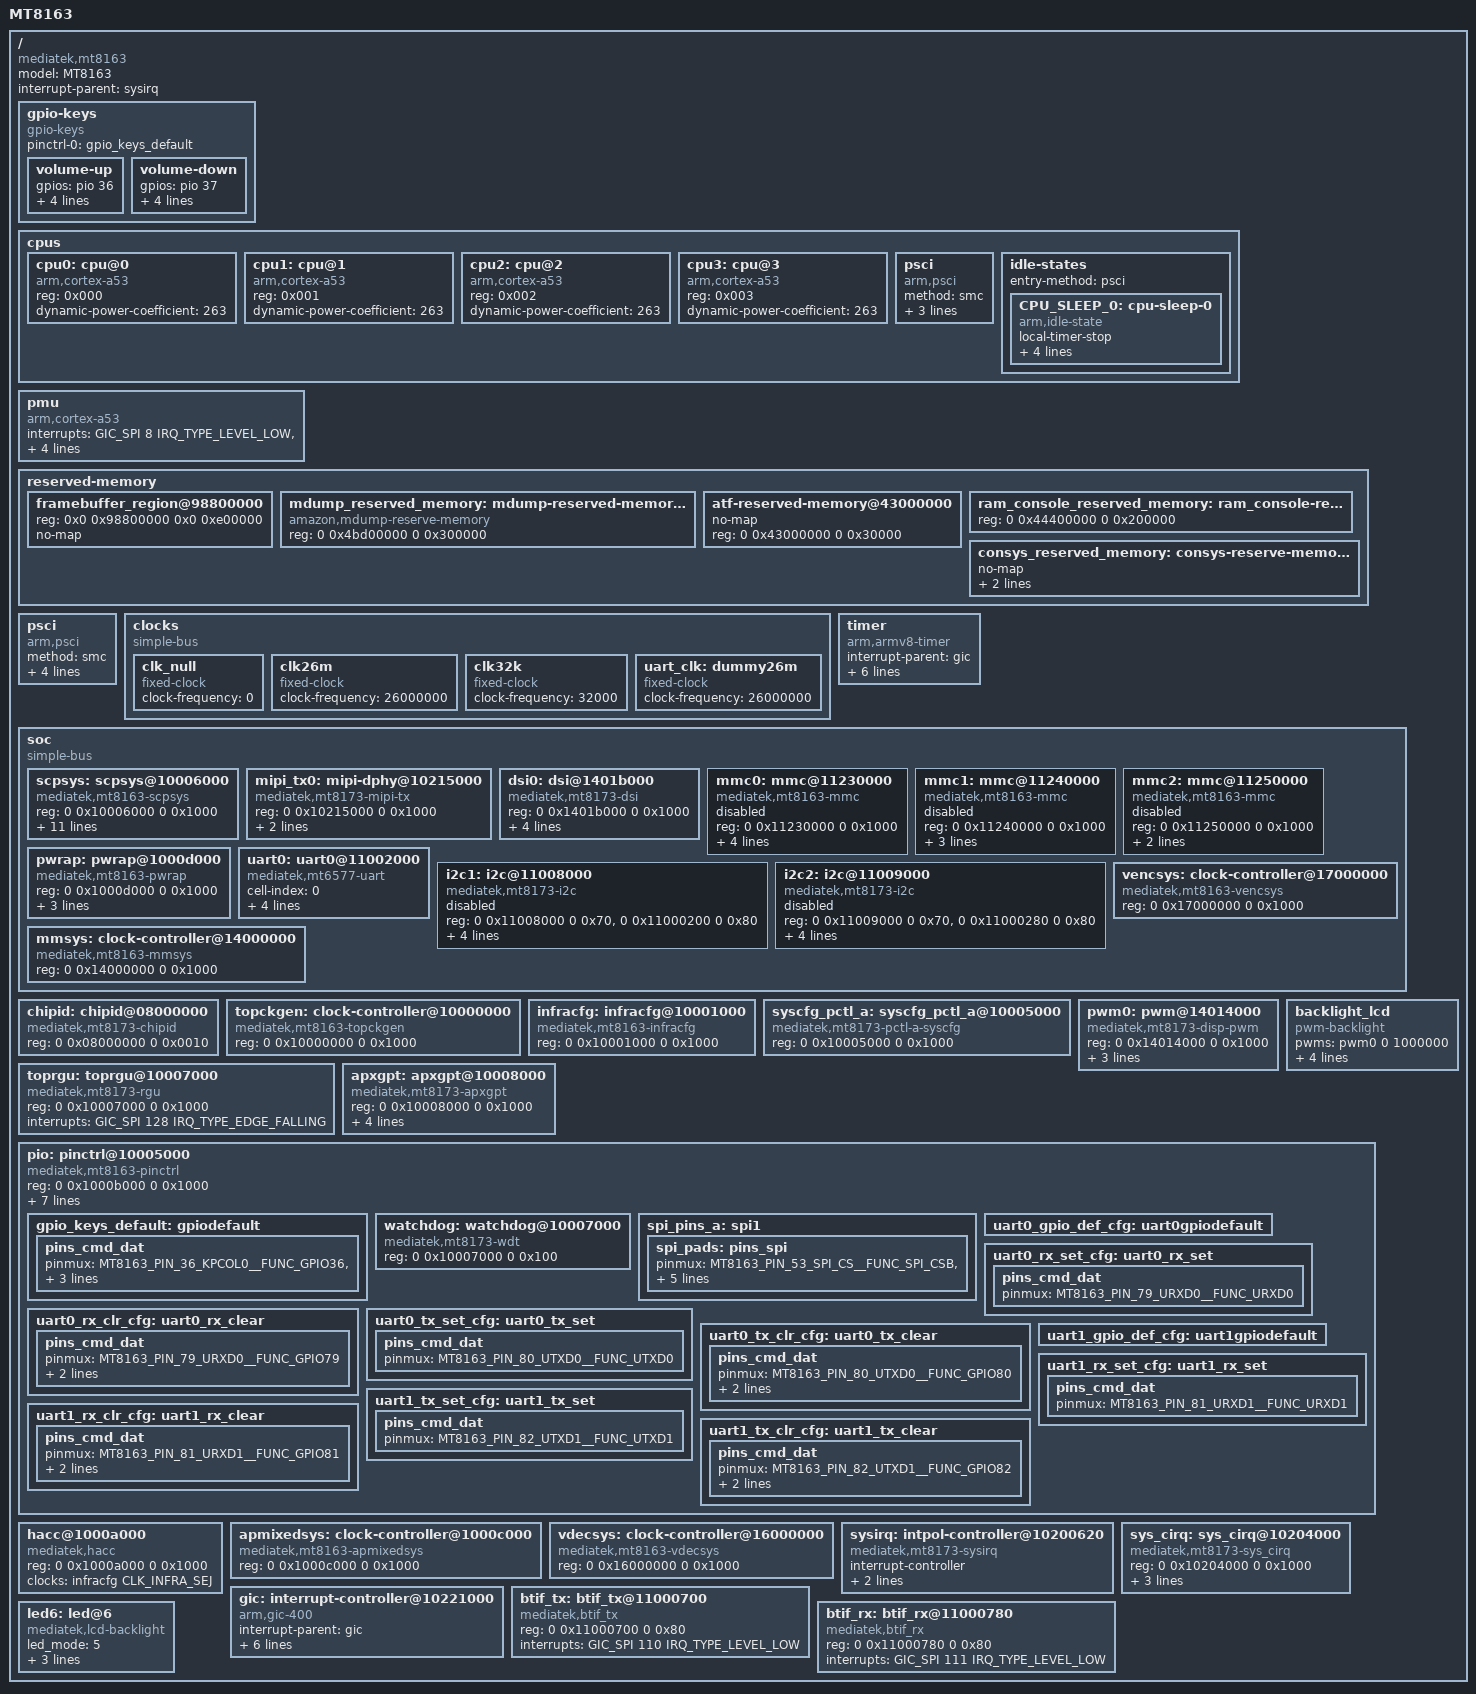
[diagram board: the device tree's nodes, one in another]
/*
 * Mediatek's MT8163 SoC device tree source
 * Copyright (c) 2014-2015 MediaTek Inc.
 *
 * This program is free software; you can redistribute it and/or modify
 * it under the terms of the GNU General Public License version 2 as
 * published by the Free Software Foundation.
 *
 * This program is distributed in the hope that it will be useful,
 * MERCHANTABILITY or FITNESS FOR A PARTICULAR PURPOSE.  See the
 * GNU General Public License for more details.
 */

#include <dt-bindings/clock/mt8163-clk.h>
#include <dt-bindings/power/mt8163-power.h>
#include <dt-bindings/interrupt-controller/irq.h>
#include <dt-bindings/interrupt-controller/arm-gic.h>
#include <dt-bindings/reset-controller/mt8163-resets.h>
#include "mt8163-pinfunc.h"
#include <dt-bindings/gpio/gpio.h> 
/ {
	model = "MT8163";
	compatible = "mediatek,mt8163";
	interrupt-parent = <&sysirq>;
	#address-cells = <2>;
	#size-cells = <2>;
        gpio-keys {
		    compatible = "gpio-keys";
		    pinctrl-names = "default";
		    pinctrl-0 = <&gpio_keys_default>;

		    volume-up {
			    gpios = <&pio 36 GPIO_ACTIVE_HIGH>;
			    label = "volume_up";
			    linux,code = <115>;
			    wakeup-source;
			    debounce-interval = <15>;
		    };

		    volume-down {
			    gpios = <&pio 37 GPIO_ACTIVE_HIGH>;
			    label = "volume_down";
			    linux,code = <114>;
			    wakeup-source;
			debounce-interval = <15>;
		};	
};
	cpus {
		#address-cells = <1>;
		#size-cells = <0>;
		cpu0: cpu@0 {
			device_type = "cpu";
			compatible = "arm,cortex-a53";
			reg = <0x000>;
	//		enable-method = "psci";
			dynamic-power-coefficient = <263>;
		};
        cpu1: cpu@1 {
			device_type = "cpu";
			compatible = "arm,cortex-a53";
			reg = <0x001>;
		//	enable-method = "psci";
			dynamic-power-coefficient = <263>;
		};

		cpu2: cpu@2 {
			device_type = "cpu";
			compatible = "arm,cortex-a53";
			reg = <0x002>;
			//enable-method = "psci";
			dynamic-power-coefficient = <263>;
		};
		cpu3: cpu@3 {
			device_type = "cpu";
			compatible = "arm,cortex-a53";
			reg = <0x003>;
			//enable-method = "psci";
			dynamic-power-coefficient = <263>;
		};
	psci {
		compatible  = "arm,psci";
		method      = "smc";
		cpu_suspend = <0x84000001>;
		cpu_off     = <0x84000002>;
		cpu_on      = <0x84000003>;
	};

		idle-states {
			entry-method = "psci";

			CPU_SLEEP_0: cpu-sleep-0 {
				compatible = "arm,idle-state";
				local-timer-stop;
				entry-latency-us = <639>;
				exit-latency-us = <680>;
				min-residency-us = <1088>;
				arm,psci-suspend-param = <0x0010000>;
			};
		};
	};


	pmu {
		compatible = "arm,cortex-a53";
		interrupts = <GIC_SPI 8 IRQ_TYPE_LEVEL_LOW>,
			<GIC_SPI 9 IRQ_TYPE_LEVEL_LOW>,
			<GIC_SPI 10 IRQ_TYPE_LEVEL_LOW>,
			<GIC_SPI 11 IRQ_TYPE_LEVEL_LOW>;
		interrupt-affinity = <&cpu0>,
				<&cpu1>,
				<&cpu2>,
				<&cpu3>;
	};
	
	reserved-memory {
		#address-cells = <2>;
		#size-cells = <2>;
		ranges;
		framebuffer_region@98800000 {
			reg = <0x0 0x98800000 0x0 0xe00000>;
			no-map;
		};

		mdump_reserved_memory: mdump-reserved-memory@4bd00000 {
			compatible = "amazon,mdump-reserve-memory";
			reg = <0 0x4bd00000 0 0x300000>;
		};

		atf-reserved-memory@43000000 {
			no-map;
			reg = <0 0x43000000 0 0x30000>;
		};

		ram_console_reserved_memory: ram_console-reserved-memory@44400000{
			reg = <0 0x44400000 0 0x200000>;
		};

		consys_reserved_memory: consys-reserve-memory {
			no-map;
			size = <0 0x200000>;
			alignment = <0 0x200000>;
		};
	};

	psci {
		compatible  = "arm,psci";
		method      = "smc";
		cpu_suspend = <0x84000001>;
		cpu_off     = <0x84000002>;
		cpu_on      = <0x84000003>;
		affinity_info = <0x84000004>;
	};

	clocks {
		#address-cells = <2>;
		#size-cells = <2>;
		compatible = "simple-bus";
		ranges;

		clk_null: clk_null {
			compatible = "fixed-clock";
			#clock-cells = <0>;
			clock-frequency = <0>;
		};

		clk26m: clk26m {
			compatible = "fixed-clock";
			#clock-cells = <0>;
			clock-frequency = <26000000>;
		};

		clk32k: clk32k {
			compatible = "fixed-clock";
			#clock-cells = <0>;
			clock-frequency = <32000>;
		};

		uart_clk: dummy26m {
			compatible = "fixed-clock";
			clock-frequency = <26000000>;
			#clock-cells = <0>;
		};
	};
	
	

	timer {
		compatible = "arm,armv8-timer";
		interrupt-parent = <&gic>;
		interrupts = <GIC_PPI 13
			     (GIC_CPU_MASK_SIMPLE(4) | IRQ_TYPE_LEVEL_LOW)>,
			     <GIC_PPI 14
			     (GIC_CPU_MASK_SIMPLE(4) | IRQ_TYPE_LEVEL_LOW)>,
			     <GIC_PPI 11
			     (GIC_CPU_MASK_SIMPLE(4) | IRQ_TYPE_LEVEL_LOW)>,
			     <GIC_PPI 10
			     (GIC_CPU_MASK_SIMPLE(4) | IRQ_TYPE_LEVEL_LOW)>;
		clock-frequency = <13000000>;
	};

	soc {
		#address-cells = <2>;
		#size-cells = <2>;
		compatible = "simple-bus";
		ranges;

		scpsys: scpsys@10006000 {
			compatible = "mediatek,mt8163-scpsys", "syscon";
			#power-domain-cells = <1>;
			reg = <0 0x10006000 0 0x1000>;
			interrupts =	<GIC_SPI 163 IRQ_TYPE_LEVEL_LOW>,
					<GIC_SPI 164 IRQ_TYPE_LEVEL_LOW>,
					<GIC_SPI 165 IRQ_TYPE_LEVEL_LOW>,
					<GIC_SPI 166 IRQ_TYPE_LEVEL_LOW>,
					<GIC_SPI 167 IRQ_TYPE_LEVEL_LOW>,
					<GIC_SPI 168 IRQ_TYPE_LEVEL_LOW>,
					<GIC_SPI 169 IRQ_TYPE_LEVEL_LOW>,
					<GIC_SPI 170 IRQ_TYPE_LEVEL_LOW>;
			infracfg = <&infracfg>;
			clocks = <&topckgen CLK_TOP_MFG_SEL>,
				 <&topckgen CLK_TOP_MM_SEL>;
			clock-names = "mfg", "mm";
		};
mipi_tx0: mipi-dphy@10215000 {
			compatible = "mediatek,mt8173-mipi-tx";
			reg = <0 0x10215000 0 0x1000>;
			clocks = <&clk26m>;
			clock-output-names = "mipi_tx0_pll";
			#clock-cells = <0>;
			#phy-cells = <0>;
			status = "okay";
		};
dsi0: dsi@1401b000 {
	compatible = "mediatek,mt8173-dsi";
	reg = <0 0x1401b000 0 0x1000>;
	interrupts = <GIC_SPI 192 IRQ_TYPE_LEVEL_LOW>;
			clocks = <&mmsys CLK_MM_DSI_ENGINE>,
				 <&mmsys CLK_MM_DSI_DIGITAL>,
				 <&mipi_tx0>;
	clock-names = "engine", "digital", "hs";
	phys = <&mipi_tx0>;
	phy-names = "dphy";

};
			mmc0: mmc@11230000 {
			compatible = "mediatek,mt8163-mmc";
			reg = <0 0x11230000 0 0x1000>;
			interrupts = <GIC_SPI 79 IRQ_TYPE_LEVEL_LOW>;
			infracfg = <&infracfg>;
			clocks = <&infracfg CLK_INFRA_MSDC3>,
					<&infracfg CLK_INFRA_MSDC0>,
					<&clk_null>;
			clock-names = "extra", "source", "hclk";
			status = "disabled";
		};

		mmc1: mmc@11240000 {
			compatible = "mediatek,mt8163-mmc";
			reg = <0 0x11240000 0 0x1000>;
			interrupts = <GIC_SPI 80 IRQ_TYPE_LEVEL_LOW>;
			clocks = <&infracfg CLK_INFRA_MSDC1>,
					<&topckgen CLK_TOP_AXI_SEL>,
                    <&clk_null>;
			clock-names = "extra", "source", "hclk";
			status = "disabled";
		};

        mmc2: mmc@11250000 {
            compatible = "mediatek,mt8163-mmc";
            reg = <0 0x11250000 0 0x1000>;
            interrupts = <GIC_SPI 81 IRQ_TYPE_LEVEL_LOW>;
            clocks = <&infracfg CLK_INFRA_MSDC2>,
                     <&clk_null>;
           clock-names = "source", "hclk";
           status = "disabled";
           };
		pwrap: pwrap@1000d000 {
			compatible = "mediatek,mt8163-pwrap";
			reg = <0 0x1000d000 0 0x1000>;
			reg-names = "pwrap";
			interrupts = <GIC_SPI 161 IRQ_TYPE_LEVEL_HIGH>;
			clocks = <&topckgen CLK_TOP_PMICSPI_SEL>,
				 <&infracfg CLK_INFRA_PMIC_AP>;
			clock-names = "spi",
				      "wrap";
		};
		uart0: uart0@11002000 {
			cell-index = <0>;
			compatible = "mediatek,mt6577-uart";
			reg = <0 0x11002000 0 0x400>; /* UART base */
			interrupts = <GIC_SPI 91 IRQ_TYPE_LEVEL_LOW>;
			clocks = <&infracfg CLK_INFRA_UART0_SEL>, <&infracfg CLK_INFRA_UART0>;
			clock-names = "baud", "bus";
			status = "okay";
		};
        i2c1: i2c@11008000 {
			compatible = "mediatek,mt8173-i2c";
			reg = <0 0x11008000 0 0x70>,
			      <0 0x11000200 0 0x80>;
			interrupts = <GIC_SPI 85 IRQ_TYPE_LEVEL_LOW>;
			clock-div = <8>;
			clocks = <&infracfg CLK_INFRA_I2C1>, <&infracfg CLK_INFRA_AP_DMA>;
			clock-names = "main", "dma";
			#address-cells = <1>;
			#size-cells = <0>;
			status = "disabled";
		};
		i2c2: i2c@11009000 {
			compatible = "mediatek,mt8173-i2c";
			reg = <0 0x11009000 0 0x70>,
			      <0 0x11000280 0 0x80>;
			interrupts = <GIC_SPI 86 IRQ_TYPE_LEVEL_LOW>;
			clock-div = <10>;
			clocks = <&infracfg CLK_INFRA_I2C2>, <&infracfg CLK_INFRA_AP_DMA>;
			clock-names = "main", "dma";
			#address-cells = <1>;
			#size-cells = <0>;
			status = "disabled";
		};
		vencsys: clock-controller@17000000 {
			compatible = "mediatek,mt8163-vencsys", "syscon";
			reg = <0 0x17000000 0 0x1000>;
			#clock-cells = <1>;
		};
		mmsys: clock-controller@14000000 {
			compatible = "mediatek,mt8163-mmsys", "syscon";
			reg = <0 0x14000000 0 0x1000>;
			#clock-cells = <1>;
		};

		};
		chipid: chipid@08000000 {
			compatible = "mediatek,mt8173-chipid";
			reg = <0 0x08000000 0 0x0010>;
		};

		topckgen: clock-controller@10000000 {
			compatible = "mediatek,mt8163-topckgen";
			reg = <0 0x10000000 0 0x1000>;
			#clock-cells = <1>;
		};

		infracfg: infracfg@10001000 {
			compatible = "mediatek,mt8163-infracfg", "syscon";
			reg = <0 0x10001000 0 0x1000>;
			#clock-cells = <1>;
			#reset-cells = <1>;
		};

		syscfg_pctl_a: syscfg_pctl_a@10005000 {
			compatible = "mediatek,mt8173-pctl-a-syscfg", "syscon";
			reg = <0 0x10005000 0 0x1000>;
		};
        pwm0: pwm@14014000 {
			compatible ="mediatek,mt8173-disp-pwm",
                        "mediatek,mt6595-disp-pwm";
			reg = <0 0x14014000 0 0x1000>;
			#pwm-cells = <2>;
			clocks = <&mmsys CLK_MM_DISP_PWM_26M>,
				 <&mmsys CLK_MM_DISP_PWM_MM>;
			clock-names = "main", "mm";
		    pinctrl-names = "default";
	        pinctrl-0 = <&disp_pwm0_pins>;
	        status = "okay";
		};
     	backlight_lcd: backlight_lcd {
		compatible = "pwm-backlight";
		pwms = <&pwm0 0 1000000>;
		brightness-levels = <
			  0  16  32  48  64  80  96 112
			128 144 160 176 192 208 224 240
			255
		>;
		default-brightness-level = <9>;
		power-supply = <&mt6323_vio18_reg>;

	};
		toprgu: toprgu@10007000 {
			compatible = "mediatek,mt8173-rgu";
			reg = <0 0x10007000 0 0x1000>;
			interrupts = <GIC_SPI 128 IRQ_TYPE_EDGE_FALLING>;
			#reset-cells = <1>;
		};

		apxgpt: apxgpt@10008000 {
			compatible = "mediatek,mt8173-apxgpt";
			reg = <0 0x10008000 0 0x1000>;
			interrupts = <GIC_SPI 152 IRQ_TYPE_LEVEL_LOW>;
			clocks = <&infracfg CLK_INFRA_APXGPT>,
				 <&infracfg CLK_INFRA_CLK_13M>,
				 <&topckgen CLK_TOP_RTC_SEL>;
			clock-names = "bus",
				      "clk13m",
				      "rtc_sel";
		};


		pio: pinctrl@10005000 {
			compatible = "mediatek,mt8163-pinctrl";
			reg = <0 0x1000b000 0 0x1000>;
			mediatek,pctl-regmap = <&syscfg_pctl_a>;
			pins-are-numbered;
			gpio-controller;
			#gpio-cells = <2>;
			interrupt-controller;
			#interrupt-cells = <2>;
			interrupts = <GIC_SPI 153 IRQ_TYPE_LEVEL_HIGH>,
				     <GIC_SPI 154 IRQ_TYPE_LEVEL_HIGH>,
				     <GIC_SPI 155 IRQ_TYPE_LEVEL_HIGH>;
	gpio_keys_default: gpiodefault {
		pins_cmd_dat {
			pinmux = <MT8163_PIN_36_KPCOL0__FUNC_GPIO36>,
				 <MT8163_PIN_37_KPCOL1__FUNC_GPIO37>;
			bias-pull-up;
			input-enable;
		};
	};
			watchdog: watchdog@10007000 {
			compatible = "mediatek,mt8173-wdt",
				     "mediatek,mt6589-wdt";
			reg = <0 0x10007000 0 0x100>;
		    };

			spi_pins_a: spi1 {
				spi_pads: pins_spi {
					pinmux = <MT8163_PIN_53_SPI_CS__FUNC_SPI_CSB>,
						 <MT8163_PIN_54_SPI_CK__FUNC_SPI_CLK>,
						 <MT8163_PIN_55_SPI_MI__FUNC_SPI_MI>,
						 <MT8163_PIN_56_SPI_MO__FUNC_SPI_MO>;
					bias-disable;
					drive-strength = <MTK_DRIVE_8mA>;
				};
			};


			/* UART GPIO Settings - Start */
			/* UART0: rx set, rx clear, tx clear, tx clear*/
			uart0_gpio_def_cfg:uart0gpiodefault {

			};
			uart0_rx_set_cfg:uart0_rx_set {
				pins_cmd_dat {
					pinmux = <MT8163_PIN_79_URXD0__FUNC_URXD0>;
				};
			};
			uart0_rx_clr_cfg:uart0_rx_clear  {
				pins_cmd_dat {
					pinmux = <MT8163_PIN_79_URXD0__FUNC_GPIO79>;
					slew-rate = <1>;
					output-high;
				};
			};
			uart0_tx_set_cfg:uart0_tx_set  {
				pins_cmd_dat {
					pinmux = <MT8163_PIN_80_UTXD0__FUNC_UTXD0>;
				};
			};
			uart0_tx_clr_cfg:uart0_tx_clear  {
				pins_cmd_dat {
					pinmux = <MT8163_PIN_80_UTXD0__FUNC_GPIO80>;
					slew-rate = <1>;
					output-high;
				};
			};

			/* UART1: rx set, rx clear, tx clear, tx clear*/
			uart1_gpio_def_cfg:uart1gpiodefault {

			};
			uart1_rx_set_cfg:uart1_rx_set {
				pins_cmd_dat {
					pinmux = <MT8163_PIN_81_URXD1__FUNC_URXD1>;
				};
			};
			uart1_rx_clr_cfg:uart1_rx_clear {
				pins_cmd_dat {
					pinmux = <MT8163_PIN_81_URXD1__FUNC_GPIO81>;
					slew-rate = <1>;
					output-high;
				};
			};
			uart1_tx_set_cfg:uart1_tx_set {
				pins_cmd_dat {
					pinmux = <MT8163_PIN_82_UTXD1__FUNC_UTXD1>;
				};
			};
			uart1_tx_clr_cfg:uart1_tx_clear {
				pins_cmd_dat {
					pinmux = <MT8163_PIN_82_UTXD1__FUNC_GPIO82>;
					slew-rate = <1>;
					output-high;
				};
			};			
/* UART GPIO Settings - End */
		};



		hacc@1000a000 {
			compatible = "mediatek,hacc";
			reg = <0 0x1000a000 0 0x1000>;
			clocks = <&infracfg CLK_INFRA_SEJ>;
			clock-names = "main";
		};

		apmixedsys: clock-controller@1000c000 {
			compatible = "mediatek,mt8163-apmixedsys";
			reg = <0 0x1000c000 0 0x1000>;
			#clock-cells = <1>;
		};
        vdecsys: clock-controller@16000000 {
			compatible = "mediatek,mt8163-vdecsys", "syscon";
			reg = <0 0x16000000 0 0x1000>;
			#clock-cells = <1>;
		};
	
		sysirq: intpol-controller@10200620 {
			compatible = "mediatek,mt8173-sysirq",
				     "mediatek,mt6577-sysirq";
			interrupt-controller;
			#interrupt-cells = <3>;
			interrupt-parent = <&gic>;
			reg = <0 0x10200620 0 0x20>;
		};


		sys_cirq: sys_cirq@10204000 {
			compatible = "mediatek,mt8173-sys_cirq",
				     "mediatek,mt6735-sys_cirq";
			reg = <0 0x10204000 0 0x1000>;
			interrupts = <GIC_SPI 240 IRQ_TYPE_LEVEL_LOW>;
			mediatek,cirq_num = <169>;
			mediatek,spi_start_offset = <72>;
		};

		
		gic: interrupt-controller@10221000 {
			compatible = "arm,gic-400";
			#interrupt-cells = <3>;
			interrupt-parent = <&gic>;
			interrupt-controller;
			reg = <0 0x10221000 0 0x1000>,
			      <0 0x10222000 0 0x2000>,
			      <0 0x10224000 0 0x2000>,
			      <0 0x10226000 0 0x2000>;
			interrupts = <GIC_PPI 9
				     (GIC_CPU_MASK_SIMPLE(4) | IRQ_TYPE_LEVEL_HIGH)>;
		};

		btif_tx: btif_tx@11000700 {
			compatible = "mediatek,btif_tx";
			reg = <0 0x11000700 0 0x80>;
			interrupts = <GIC_SPI 110 IRQ_TYPE_LEVEL_LOW>;
		};

		btif_rx: btif_rx@11000780 {
			compatible = "mediatek,btif_rx";
			reg = <0 0x11000780 0 0x80>;
			interrupts = <GIC_SPI 111 IRQ_TYPE_LEVEL_LOW>;
		};

		

//Needed to make bootloader happy.
		led6:led@6 {
			compatible = "mediatek,lcd-backlight";
			led_mode = <5>;
			data = < >;
			pwm_config = <0 0 0 0 0>;
			gpios = <&pio 43 0>;
		};
/* led end*/
};



